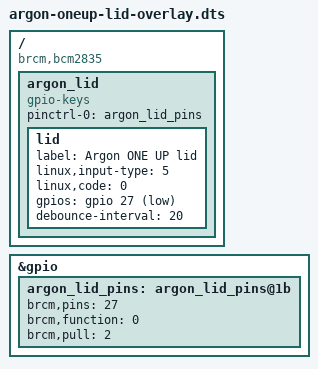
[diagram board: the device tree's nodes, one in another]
// SPDX-License-Identifier: GPL-3.0-or-later
//
// The Argon ONE UP's lid, as a standard Linux lid switch.
//
// GPIO27 reads high with the lid open and low with it closed, through the pull-up, with one
// clean edge per movement (ONEUP-GPIO27, observed in T20). This hands it to the kernel's
// gpio-keys driver as SW_LID, so logind handles the lid as on any laptop: what closing it does
// is HandleLidSwitch= in logind.conf. No daemon is involved, and none needs any privilege for
// it.
//
// Modelled on the Raspberry Pi kernel's own gpio-key overlay, with the two properties that
// make a switch of a key: linux,input-type = EV_SW, linux,code = SW_LID.
//
// The kernel then owns GPIO27. The vendor's argononeupd requests the same line, so it must be
// stopped and disabled before this is enabled.
//
// Install: copy the compiled argon-oneup-lid.dtbo to /boot/firmware/overlays/, add
//   dtoverlay=argon-oneup-lid
// to /boot/firmware/config.txt, and reboot.

/dts-v1/;
/plugin/;

/ {
	compatible = "brcm,bcm2835";

	fragment@0 {
		target = <&gpio>;
		__overlay__ {
			argon_lid_pins: argon_lid_pins@1b {
				brcm,pins = <27>;
				brcm,function = <0>;	/* input */
				brcm,pull = <2>;	/* pull-up */
			};
		};
	};

	fragment@1 {
		target-path = "/";
		__overlay__ {
			argon_lid: argon_lid {
				compatible = "gpio-keys";
				pinctrl-names = "default";
				pinctrl-0 = <&argon_lid_pins>;
				status = "okay";

				lid {
					label = "Argon ONE UP lid";
					linux,input-type = <5>;	/* EV_SW */
					linux,code = <0>;	/* SW_LID: 1 = closed */
					/* Active low: closed pulls the line low, which reports the switch on. */
					gpios = <&gpio 27 1>;
					/* T20 saw no bounce; this only guards a noisy unit. */
					debounce-interval = <20>;
				};
			};
		};
	};
};
